# nrf5340_application register map
Vendor: Nordic Semiconductor; Series: nrf53; File version: 1
CPU: CM33 r0p4, little endian, MPU, FPU, 3 interrupt priority bits, 69 interrupts
Registers are 32-bit, read-write, reset 0x0 unless marked. A register's access mark holds for its fields unless they carry their own. Offsets are from the block's base; [hi:lo] are bit positions; {n}, {i} and the like mark numbered series.

## CC_RNG_S — CRYPTOCELL RNG engine
Base 0x50845000; alternate view of CC_AES_S
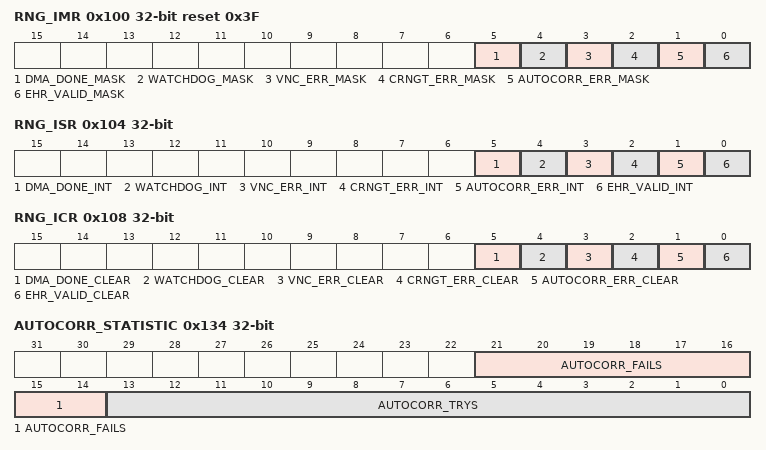
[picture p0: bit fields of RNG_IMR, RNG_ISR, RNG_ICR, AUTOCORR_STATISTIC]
0x100 RNG_IMR reset 0x3F — Interrupt mask register. Each bit of this register holds the mask of a single interrupt source.
  [5] DMA_DONE_MASK — See RNG_ISR for explanation on this interrupt.
    0=IRQEnable (Do not mask the RNG DMA completion interrupt i.e. interrupt is generated); 1=IRQDisable (Mask the RNG DMA completion interrupt i.e. no interrupt is generated)
  [4] WATCHDOG_MASK — See RNG_ISR for explanation on this interrupt.
    0=IRQEnable (Do not mask the watchdog interrupt i.e. interrupt is generated); 1=IRQDisable (Mask the watchdog interrupt i.e. no interrupt is generated)
  [3] VNC_ERR_MASK — See RNG_ISR for explanation on this interrupt.
    0=IRQEnable (Do not mask the von Neumann corrector error interrupt i.e. interrupt is generated); 1=IRQDisable (Mask the von Neumann corrector error interrupt i.e. no interrupt is generated)
  [2] CRNGT_ERR_MASK — See RNG_ISR for explanation on this interrupt.
    0=IRQEnable (Do not mask the CRNGT error interrupt i.e. interrupt is generated); 1=IRQDisable (Mask the CRNGT error interrupt i.e. no interrupt is generated)
  [1] AUTOCORR_ERR_MASK — See RNG_ISR for explanation on this interrupt.
    0=IRQEnable (Do not mask autocorrelation interrupt i.e. interrupt is generated); 1=IRQDisable (Mask autocorrelation interrupt i.e. no interrupt is generated)
  [0] EHR_VALID_MASK — See RNG_ISR for explanation on this interrupt.
    0=IRQEnable (Do not mask EHR interrupt i.e. interrupt is generated); 1=IRQDisable (Mask EHR interrupt i.e. no interrupt is generated)
0x104 RNG_ISR ro — Interrupt status register. Each bit of this register holds the interrupt status of a single interrupt source. If corresponding RNG_IMR bit is unmasked, an interrupt is generated.
  [5] DMA_DONE_INT — RNG DMA to SRAM is completed.
  [4] WATCHDOG_INT — Maximum number of CPU clock cycles per sample have been exceeded. See RNG_WATCHDOG_VAL for more information.
  [3] VNC_ERR_INT — von Neumann corrector error. Failure occurs if 32 consecutive collected bits are identical, ZERO, or ONE.
  [2] CRNGT_ERR_INT — Continuous random number generator test error. Failure occurs when two consecutive blocks of 16 collected bits are equal.
  [1] AUTOCORR_ERR_INT — Autocorrelation error. Failure occurs when autocorrelation test has failed four times in a row. Once set, the TRNG ceases to function until next reset.
  [0] EHR_VALID_INT — 192-bits have been collected and are ready to be read.
0x108 RNG_ICR wo — Interrupt clear register. Writing a 1 bit into a field in this register will clear the corresponding bit in RNG_ISR.
  [5] DMA_DONE_CLEAR — Writing value '1' clears corresponding bit in RNG_ISR
  [4] WATCHDOG_CLEAR — Writing value '1' clears corresponding bit in RNG_ISR
  [3] VNC_ERR_CLEAR — Writing value '1' clears corresponding bit in RNG_ISR
  [2] CRNGT_ERR_CLEAR — Writing value '1' clears corresponding bit in RNG_ISR
  [1] AUTOCORR_ERR_CLEAR — Cannot be cleared by software! Only RNG reset clears this bit.
  [0] EHR_VALID_CLEAR — Writing value '1' clears corresponding bit in RNG_ISR
0x10C TRNG_CONFIG — TRNG ring oscillator length configuration
  [1:0] ROSC_LEN — Set the length of the oscillator ring (= the number of inverters) out of four possible configurations.
    0=ROSC1 (Use shortest ROSC1 ring oscillator configuration.); 1=ROSC2 (Use ROSC2 ring oscillator configuration.); 2=ROSC3 (Use ROSC3 ring oscillator configuration.); 3=ROSC4 (Use longest ROSC4 ring oscillator configuration.)
0x110 TRNG_VALID ro — This register indicates if TRNG entropy collection is valid.
  [0] EHR_DATA — A value of 1 indicates that collection of bits in the TRNG is completed, and data can be read from EHR_DATA registers.
    0=NotValid (Collection of bits not valid.); 1=Valid (Collection of bits valid.)
{0x114+4i} EHR_DATA[{i}] (i=0..5) ro — Description collection: The entropy holding registers (EHR) hold 192-bits random data collected by the TRNG. The initial EHR_DATA[0] register holds the least significant bits [31:0] of the random data value.
  [31:0] VALUE — Random data value.
0x12C NOISE_SOURCE — This register controls the ring oscillator circuit used as a noise source.
  [0] ENABLE — Enable or disable the noise source.
    0=Disabled (Noise source is disabled); 1=Enabled (Noise source is enabled)
0x130 SAMPLE_CNT reset 0xFFFF — Sample count defining the number of CPU clock cycles between two consecutive noise source samples.
  [31:0] VALUE — Number of CPU clock cycles between two consecutive noise source samples.
0x134 AUTOCORR_STATISTIC — Statistics counter for autocorrelation test activations. Statistics collection is stopped if one of the counters reach its limit of all ones.
  [21:14] AUTOCORR_FAILS — Count each time an autocorrelation test fails. Any write to the field resets the counter.
  [13:0] AUTOCORR_TRYS — Count each time an autocorrelation test starts. Any write to the field resets the counter.
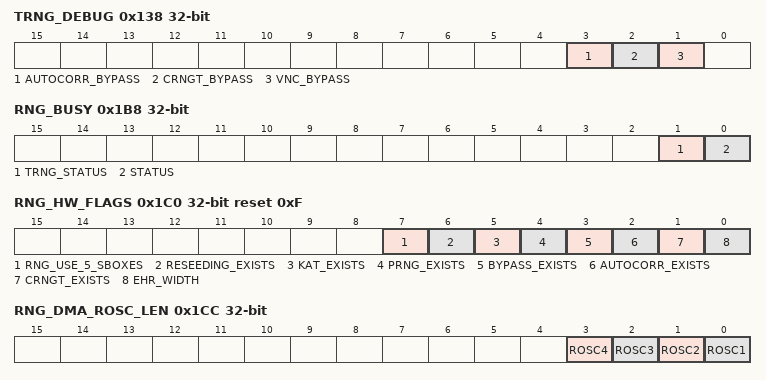
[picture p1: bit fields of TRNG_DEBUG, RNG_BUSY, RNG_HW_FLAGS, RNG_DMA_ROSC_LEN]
0x138 TRNG_DEBUG — Debug register for the TRNG. This register is used to bypass TRNG tests in hardware.
  [3] AUTOCORR_BYPASS — Bypass the autocorrelation test.
    0=Disabled (Autocorrelation test is active); 1=Enabled (Bypass the autocorrelation test)
  [2] CRNGT_BYPASS — Bypass the Continuous Random Number Generator Test (CRNGT).
    0=Disabled (CRNGT is active); 1=Enabled (Bypass CRNGT)
  [1] VNC_BYPASS — Bypass the von Neumann corrector post-processing test, including the 32 consecutive bits test.
    0=Disabled (von Neumann corrector post-processing is active); 1=Enabled (Bypass the von Neumann corrector)
0x140 RNG_SW_RESET wo — Reset the RNG engine.
  [0] RESET — Writing any value to this address resets the RNG engine. The reset takes 4 CPU clock cycles to complete.
    1=Enable (Reset RNG engine.)
0x1B8 RNG_BUSY ro — Status register for RNG engine activity.
  [1] TRNG_STATUS
    0=Idle (TRNG is idle); 1=Busy (TRNG is busy)
  [0] STATUS — RNG engine status.
    0=Idle (RNG engine is idle); 1=Busy (RNG engine is busy)
0x1BC TRNG_RESET wo — Reset the TRNG, including internal counter of collected bits and registers EHR_DATA and TRNG_VALID.
  [0] RESET — Writing any value to this address resets the internal bits counter and registers EHR_DATA and TRNG_VALID. Register NOISE_SOURCE must be disabled in order for the reset to take place.
    1=Enable (Reset TRNG.)
0x1C0 RNG_HW_FLAGS ro reset 0xF — Hardware configuration of RNG engine. Reset value holds the supported features.
  [7] RNG_USE_5_SBOXES
    0=Disable (20 SBOX AES); 1=Enable (5 SBOX AES)
  [6] RESEEDING_EXISTS — If this flag is set, the engine include support for automatic reseeding.
  [5] KAT_EXISTS — If this flag is set, the engine include support for known answer tests.
  [4] PRNG_EXISTS — If this flag is set, the engine include a pseudo-random number generator.
  [3] BYPASS_EXISTS — If this flag is set, the engine include support for bypassing TRNG tests.
  [2] AUTOCORR_EXISTS — If this flag is set, the engine include support for autocorrelation test.
  [1] CRNGT_EXISTS — If this flag is set, the engine include support for continuous random number generator test.
  [0] EHR_WIDTH — Data width supported by the entropy collector
    0=128 bits EHR width; 1=192 bits EHR width
0x1C4 RNG_CLK wo — Control clock for the RNG engine.
  [0] ENABLE — Enables clock for the RNG engine.
    0=Disable clock for RNG engine; 1=Enable clock for RNG engine
0x1C8 RNG_DMA — Writing to this register enables the RNG DMA engine.
  [0] ENABLE
    0=Disable RNG DMA engine; 1=Enable RNG DMA engine This value is cleared when the RNG DMA engine completes its operation
0x1CC RNG_DMA_ROSC_LEN — This register defines which ring oscillator length configuration should be used when using the RNG DMA engine.
  [3] ROSC4 — Use longest ROSC4 ring oscillator configuration.
    0=Disable ROSC4; 1=Enable ROSC4
  [2] ROSC3 — Use ROSC3 ring oscillator configuration.
    0=Disable ROSC3; 1=Enable ROSC3
  [1] ROSC2 — Use ROSC2 ring oscillator configuration.
    0=Disable ROSC2; 1=Enable ROSC2
  [0] ROSC1 — Use shortest ROSC1 ring oscillator configuration.
    0=Disable ROSC1; 1=Enable ROSC1
0x1D0 RNG_DMA_SRAM_ADDR — This register defines the start address in TRNG SRAM for the TRNG data to be collected by the RNG DMA engine.
  [10:0] RNG_SRAM_DMA_ADDR — Start address of the TRNG data in TRNG SRAM.
0x1D4 RNG_DMA_SAMPLES_NUM — This register defines the number of 192-bits samples that the RNG DMA engine collects per run.
  [7:0] RNG_SAMPLES_NUM — Defines the number of 192-bits samples that the DMA engine collects per run.
0x1D8 RNG_WATCHDOG_VAL — This register defines the maximum number of CPU clock cycles per TRNG collection of 192-bits samples. If the number of cycles for a collection exceeds this threshold the WATCHDOG interrupt is triggered.
  [31:0] RNG_WATCHDOG_VAL — Defines the maximum number of CPU clock cycles per TRNG collection of 192-bits samples. If the number of cycles for a collection exceeds this threshold the WATCHDOG interrupt is triggered.
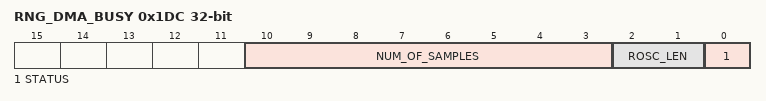
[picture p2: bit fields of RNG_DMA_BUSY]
0x1DC RNG_DMA_BUSY ro — Status register for RNG DMA engine activity.
  [10:3] NUM_OF_SAMPLES — Number of samples already collected using the current ring oscillator configuration.
  [2:1] ROSC_LEN — The active ring oscillator length configuration used by the RNG DMA engine.
    0=ROSC1 (Shortest ROSC1 ring oscillator configuration used.); 1=ROSC2 (ROSC2 ring oscillator configuration used.); 2=ROSC3 (ROSC3 ring oscillator configuration used.); 3=ROSC4 (Longest ROSC4 ring oscillator configuration used.)
  [0] STATUS — RNG DMA engine status.
    0=Idle (RNG DMA engine is idle); 1=Busy (RNG DMA engine is busy)
